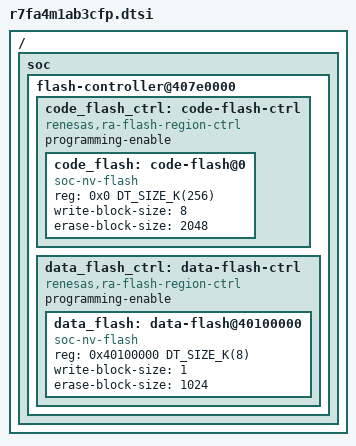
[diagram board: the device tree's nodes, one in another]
/*
 * Copyright (c) 2024-2025 Renesas Electronics Corporation
 * Copyright (c) 2025 TOKITA Hiroshi
 *
 * SPDX-License-Identifier: Apache-2.0
 */

#include <zephyr/dt-bindings/clock/ra_clock.h>
#include <arm/renesas/ra/ra4/r7fa4m1ax.dtsi>

/ {
	soc {
		flash-controller@407e0000 {
			code_flash_ctrl: code-flash-ctrl {
				compatible = "renesas,ra-flash-region-ctrl";
				programming-enable;
				#address-cells = <1>;
				#size-cells = <1>;

				code_flash: code-flash@0 {
					compatible = "soc-nv-flash";
					reg = <0x0 DT_SIZE_K(256)>;
					ranges = <0x0 0x0 DT_SIZE_K(256)>;
					write-block-size = <8>;
					erase-block-size = <2048>;
					#address-cells = <1>;
					#size-cells = <1>;
				};
			};

			data_flash_ctrl: data-flash-ctrl {
				compatible = "renesas,ra-flash-region-ctrl";
				programming-enable;
				#address-cells = <1>;
				#size-cells = <1>;

				data_flash: data-flash@40100000 {
					compatible = "soc-nv-flash";
					reg = <0x40100000 DT_SIZE_K(8)>;
					ranges = <0x0 0x40100000 DT_SIZE_K(8)>;
					write-block-size = <1>;
					erase-block-size = <1024>;
					#address-cells = <1>;
					#size-cells = <1>;
				};
			};
		};
	};
};
